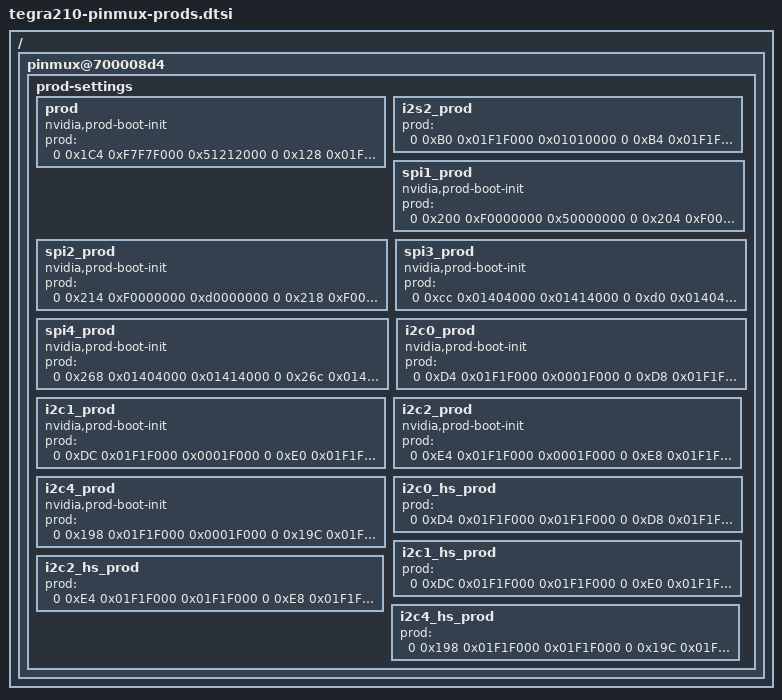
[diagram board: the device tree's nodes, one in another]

#include <dt-bindings/pinctrl/pinctrl-tegra.h>

 / {
    pinmux@700008d4 {
		prod-settings {
			#prod-cells = <4>;
			prod {
				status = "okay";
				nvidia,prod-boot-init;
				prod = <0 0x1C4 0xF7F7F000 0x51212000
					0 0x128 0x01F1F000 0x01010000  //GPIO_PZ0 DRVUP-DN
					0 0x12C 0x01F1F000 0x01010000  //GPIO_PZ1 DRVUP-DN
					0 0x1C8 0xF0003FFD 0x00001040
					0 0x1DC 0xF7F7F000 0x51212000
					0 0x1E0 0xF0003FFD 0x00001040
					0 0x23C 0x01F1F000 0x01F1F000	//TOUCH_CLK DRVUP-DN
					0 0x20 0x01F1F000 0x01010000	//AUD_MCLK
					0 0x44 0x01F1F000 0x01010000  //CAM1_MCLK DRVUP-DN
					0 0x50 0x01F1F000 0x01010000  //CAM2_MCLK DRVUP-DN
					0 0x58 0x01F1F000 0x01010000  //CAM_AF_EN DRVUP-DN
					0 0x5C 0x01F1F000 0x01010000  //CAM_FLASH_EN DRVUP-DN
					0 0xA0 0x01F1F000 0x01010000	//I2S4B DIN
					0 0xA4 0x01F1F000 0x01010000	//I2S4B DOUT
					0 0xA8 0x01F1F000 0x01010000	//I2S4B FS
					0 0xAC 0x01F1F000 0x01010000	//I2S4B SCLK
					0 0xB0 0x01F1F000 0x01F1F000	//DMIC1 CLK
					0 0xB4 0x01F1F000 0x01F1F000	//DMIC1 DATA
					0 0xB8 0x01F1F000 0x01F1F000	//DMIC2 CLK
					0 0xBC 0x01F1F000 0x01F1F000	//DMIC2 DATA
					0 0xC0 0x01F1F000 0x01F1F000	//DMIC3 CLK
					0 0xC4 0x01F1F000 0x01F1F000	//DMIC3 DATA
					1 0x00 0x00007200 0x00002000
					1 0x04 0x00007200 0x00002000
					1 0x08 0x00007200 0x00002000
					1 0x0C 0x00007200 0x00002000
					1 0x10 0x00007200 0x00002000
					1 0x14 0x00007200 0x00002000
					1 0x1C 0x00007200 0x00002000
					1 0x20 0x00007200 0x00002000
					1 0x24 0x00007200 0x00002000
					1 0x28 0x00007200 0x00002000
					1 0x2C 0x00007200 0x00002000
					1 0x30 0x00007200 0x00002000
					1 0x160 0x00001000 0x00001000>;
			};

			i2s2_prod {
				prod = <0 0xB0 0x01F1F000 0x01010000	// FS
					0 0xB4 0x01F1F000 0x01010000		// DIN
					0 0xB8 0x01F1F000 0x01010000		// DOUT
					0 0xBC 0x01F1F000 0x01010000>;		// SCLK
			};

			spi1_prod {
				nvidia,prod-boot-init;
				prod = <0 0x200 0xF0000000 0x50000000
					0 0x204 0xF0000000 0x50000000
					0 0x208 0xF0000000 0x50000000
					0 0x20c 0xF0000000 0x50000000
					0 0x210 0xF0000000 0x50000000
					1 0x50 0x00006000 0x00006040
					1 0x54 0x00006000 0x00006040
					1 0x58 0x00006000 0x00006040
					1 0x5c 0x00006000 0x00006040
					1 0x60 0x00006000 0x00006040>;
			};
			spi2_prod {
				nvidia,prod-boot-init;
				prod = <0 0x214 0xF0000000 0xd0000000
					0 0x218 0xF0000000 0xd0000000
					0 0x21c 0xF0000000 0xd0000000
					0 0x220 0xF0000000 0xd0000000
					0 0x224 0xF0000000 0xd0000000
					1 0x64 0x00006000 0x00006040
					1 0x68 0x00006000 0x00006040
					1 0x6c 0x00006000 0x00006040
					1 0x70 0x00006000 0x00006040
					1 0x74 0x00006000 0x00006040>;
			};
			spi3_prod {
				nvidia,prod-boot-init;
				prod = <0 0xcc 0x01404000 0x01414000
					0 0xd0 0x01404000 0x01414000
					0 0x140 0x01404000 0x01414000
					0 0x144 0x01404000 0x01414000>;
			};
			spi4_prod {
				nvidia,prod-boot-init;
				prod = <0 0x268 0x01404000 0x01414000
					0 0x26c 0x01404000 0x01414000
					0 0x270 0x01404000 0x01414000
					0 0x274 0x01404000 0x01414000>;
			};
			i2c0_prod {
				nvidia,prod-boot-init;
				prod = <0 0xD4 0x01F1F000 0x0001F000
					0 0xD8 0x01F1F000 0x0001F000
					1 0xBC 0x00001100 0x00000000
					1 0xC0 0x00001100 0x00000000>;
			};
			i2c1_prod {
				nvidia,prod-boot-init;
				prod = <0 0xDC 0x01F1F000 0x0001F000
					0 0xE0 0x01F1F000 0x0001F000
					1 0xC4 0x00001100 0x00000000
					1 0xC8 0x00001100 0x00000000>;
			};
			i2c2_prod {
				nvidia,prod-boot-init;
				prod = <0 0xE4 0x01F1F000 0x0001F000
					0 0xE8 0x01F1F000 0x0001F000
					1 0xCC 0x00001100 0x00000000
					1 0xD0 0x00001100 0x00000000
					0 0x60 0x01F1F000 0x0001F000
					0 0x64 0x01F1F000 0x0001F000
					1 0xD4 0x00001100 0x00000000
					1 0xD8 0x00001100 0x00000000>;
			};
			i2c4_prod {
				nvidia,prod-boot-init;
				prod = <0 0x198 0x01F1F000 0x0001F000
					0 0x19C 0x01F1F000 0x0001F000
					1 0xDC 0x00001100 0x00000000
					1 0xE0 0x00001100 0x00000000>;
			};
			i2c0_hs_prod {
				prod = <0 0xD4 0x01F1F000 0x01F1F000
					0 0xD8 0x01F1F000 0x01F1F000
					1 0xBC 0x00001100 0x00001000
					1 0xC0 0x00001100 0x00001000>;
			};
			i2c1_hs_prod {
				prod = <0 0xDC 0x01F1F000 0x01F1F000
					0 0xE0 0x01F1F000 0x01F1F000
					1 0xC4 0x00001100 0x00001000
					1 0xC8 0x00001100 0x00001000>;
			};
			i2c2_hs_prod {
				prod = <0 0xE4 0x01F1F000 0x01F1F000
					0 0xE8 0x01F1F000 0x01F1F000
					1 0xCC 0x00001100 0x00001000
					1 0xD0 0x00001100 0x00001000
					0 0x60 0x01F1F000 0x01F1F000
					0 0x64 0x01F1F000 0x01F1F000
					1 0xD4 0x00001100 0x00001000
					1 0xD8 0x00001100 0x00001000>;
			};
			i2c4_hs_prod {
				prod = <0 0x198 0x01F1F000 0x01F1F000
					0 0x19C 0x01F1F000 0x01F1F000
					1 0xDC 0x00001100 0x00001000
					1 0xE0 0x00001100 0x00001000>;
			};
		};
	};
 };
